AUTOSAR XML (schema 4-3-1)
standard types defined: Boolean, UInt8, SInt8, UInt16, SInt16, UInt32, SInt32, boolean, uint8, sint8, uint16, sint16, uint32, sint32
package /Components
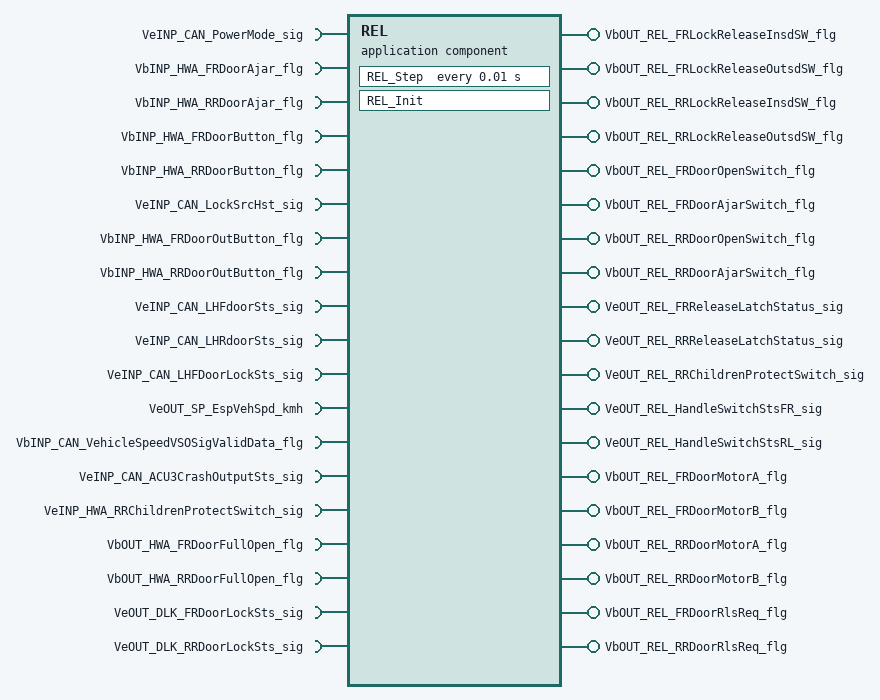
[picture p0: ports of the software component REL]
  application sw component type REL
    19 x require port:
      VeINP_CAN_PowerMode_sig: nonqueued-receiver-com-spec{data-element=VeINP_CAN_PowerMode_sig, init-value=0}, required-interface=VeINP_CAN_PowerMode_sig
      VbINP_HWA_FRDoorAjar_flg: nonqueued-receiver-com-spec{data-element=VbINP_HWA_FRDoorAjar_flg, init-value=FALSE}, required-interface=VbINP_HWA_FRDoorAjar_flg
      VbINP_HWA_RRDoorAjar_flg: nonqueued-receiver-com-spec{data-element=VbINP_HWA_RRDoorAjar_flg, init-value=FALSE}, required-interface=VbINP_HWA_RRDoorAjar_flg
      VbINP_HWA_FRDoorButton_flg: nonqueued-receiver-com-spec{data-element=VbINP_HWA_FRDoorButton_flg, init-value=FALSE}, required-interface=VbINP_HWA_FRDoorButton_flg
      VbINP_HWA_RRDoorButton_flg: nonqueued-receiver-com-spec{data-element=VbINP_HWA_RRDoorButton_flg, init-value=FALSE}, required-interface=VbINP_HWA_RRDoorButton_flg
      VeINP_CAN_LockSrcHst_sig: nonqueued-receiver-com-spec{data-element=VeINP_CAN_LockSrcHst_sig, init-value=0}, required-interface=VeINP_CAN_LockSrcHst_sig
      VbINP_HWA_FRDoorOutButton_flg: nonqueued-receiver-com-spec{data-element=VbINP_HWA_FRDoorOutButton_flg, init-value=FALSE}, required-interface=VbINP_HWA_FRDoorOutButton_flg
      VbINP_HWA_RRDoorOutButton_flg: nonqueued-receiver-com-spec{data-element=VbINP_HWA_RRDoorOutButton_flg, init-value=FALSE}, required-interface=VbINP_HWA_RRDoorOutButton_flg
      VeINP_CAN_LHFdoorSts_sig: nonqueued-receiver-com-spec{data-element=VeINP_CAN_LHFdoorSts_sig, init-value=0}, required-interface=VeINP_CAN_LHFdoorSts_sig
      VeINP_CAN_LHRdoorSts_sig: nonqueued-receiver-com-spec{data-element=VeINP_CAN_LHRdoorSts_sig, init-value=0}, required-interface=VeINP_CAN_LHRdoorSts_sig
      VeINP_CAN_LHFDoorLockSts_sig: nonqueued-receiver-com-spec{data-element=VeINP_CAN_LHFDoorLockSts_sig, init-value=0}, required-interface=VeINP_CAN_LHFDoorLockSts_sig
      VeOUT_SP_EspVehSpd_kmh: nonqueued-receiver-com-spec{data-element=VeOUT_SP_EspVehSpd_kmh, init-value=0}, required-interface=VeOUT_SP_EspVehSpd_kmh
      VbINP_CAN_VehicleSpeedVSOSigValidData_flg: nonqueued-receiver-com-spec{data-element=VbINP_CAN_VehicleSpeedVSOSigValidData_flg, init-value=FALSE}, required-interface=VbINP_CAN_VehicleSpeedVSOSigValidData_flg
      VeINP_CAN_ACU3CrashOutputSts_sig: nonqueued-receiver-com-spec{data-element=VeINP_CAN_ACU3CrashOutputSts_sig, init-value=0}, required-interface=VeINP_CAN_ACU3CrashOutputSts_sig
      VeINP_HWA_RRChildrenProtectSwitch_sig: nonqueued-receiver-com-spec{data-element=VeINP_HWA_RRChildrenProtectSwitch_sig, init-value=0}, required-interface=VeINP_HWA_RRChildrenProtectSwitch_sig
      VbOUT_HWA_FRDoorFullOpen_flg: nonqueued-receiver-com-spec{data-element=VbOUT_HWA_FRDoorFullOpen_flg, init-value=FALSE}, required-interface=VbOUT_HWA_FRDoorFullOpen_flg
      VbOUT_HWA_RRDoorFullOpen_flg: nonqueued-receiver-com-spec{data-element=VbOUT_HWA_RRDoorFullOpen_flg, init-value=FALSE}, required-interface=VbOUT_HWA_RRDoorFullOpen_flg
      VeOUT_DLK_FRDoorLockSts_sig: nonqueued-receiver-com-spec{data-element=VeOUT_DLK_FRDoorLockSts_sig, init-value=0}, required-interface=VeOUT_DLK_FRDoorLockSts_sig
      VeOUT_DLK_RRDoorLockSts_sig: nonqueued-receiver-com-spec{data-element=VeOUT_DLK_RRDoorLockSts_sig, init-value=0}, required-interface=VeOUT_DLK_RRDoorLockSts_sig
    19 x provide port:
      VbOUT_REL_FRLockReleaseInsdSW_flg: nonqueued-sender-com-spec{data-element=VbOUT_REL_FRLockReleaseInsdSW_flg, init-value=FALSE}, provided-interface=VbOUT_REL_FRLockReleaseInsdSW_flg
      VbOUT_REL_FRLockReleaseOutsdSW_flg: nonqueued-sender-com-spec{data-element=VbOUT_REL_FRLockReleaseOutsdSW_flg, init-value=FALSE}, provided-interface=VbOUT_REL_FRLockReleaseOutsdSW_flg
      VbOUT_REL_RRLockReleaseInsdSW_flg: nonqueued-sender-com-spec{data-element=VbOUT_REL_RRLockReleaseInsdSW_flg, init-value=FALSE}, provided-interface=VbOUT_REL_RRLockReleaseInsdSW_flg
      VbOUT_REL_RRLockReleaseOutsdSW_flg: nonqueued-sender-com-spec{data-element=VbOUT_REL_RRLockReleaseOutsdSW_flg, init-value=FALSE}, provided-interface=VbOUT_REL_RRLockReleaseOutsdSW_flg
      VbOUT_REL_FRDoorOpenSwitch_flg: nonqueued-sender-com-spec{data-element=VbOUT_REL_FRDoorOpenSwitch_flg, init-value=FALSE}, provided-interface=VbOUT_REL_FRDoorOpenSwitch_flg
      VbOUT_REL_FRDoorAjarSwitch_flg: nonqueued-sender-com-spec{data-element=VbOUT_REL_FRDoorAjarSwitch_flg, init-value=FALSE}, provided-interface=VbOUT_REL_FRDoorAjarSwitch_flg
      VbOUT_REL_RRDoorOpenSwitch_flg: nonqueued-sender-com-spec{data-element=VbOUT_REL_RRDoorOpenSwitch_flg, init-value=FALSE}, provided-interface=VbOUT_REL_RRDoorOpenSwitch_flg
      VbOUT_REL_RRDoorAjarSwitch_flg: nonqueued-sender-com-spec{data-element=VbOUT_REL_RRDoorAjarSwitch_flg, init-value=FALSE}, provided-interface=VbOUT_REL_RRDoorAjarSwitch_flg
      VeOUT_REL_FRReleaseLatchStatus_sig: nonqueued-sender-com-spec{data-element=VeOUT_REL_FRReleaseLatchStatus_sig, init-value=0}, provided-interface=VeOUT_REL_FRReleaseLatchStatus_sig
      VeOUT_REL_RRReleaseLatchStatus_sig: nonqueued-sender-com-spec{data-element=VeOUT_REL_RRReleaseLatchStatus_sig, init-value=0}, provided-interface=VeOUT_REL_RRReleaseLatchStatus_sig
      VeOUT_REL_RRChildrenProtectSwitch_sig: nonqueued-sender-com-spec{data-element=VeOUT_REL_RRChildrenProtectSwitch_sig, init-value=0}, provided-interface=VeOUT_REL_RRChildrenProtectSwitch_sig
      VeOUT_REL_HandleSwitchStsFR_sig: nonqueued-sender-com-spec{data-element=VeOUT_REL_HandleSwitchStsFR_sig, init-value=0}, provided-interface=VeOUT_REL_HandleSwitchStsFR_sig
      VeOUT_REL_HandleSwitchStsRL_sig: nonqueued-sender-com-spec{data-element=VeOUT_REL_HandleSwitchStsRL_sig, init-value=0}, provided-interface=VeOUT_REL_HandleSwitchStsRL_sig
      VbOUT_REL_FRDoorMotorA_flg: nonqueued-sender-com-spec{data-element=VbOUT_REL_FRDoorMotorA_flg, init-value=FALSE}, provided-interface=VbOUT_REL_FRDoorMotorA_flg
      VbOUT_REL_FRDoorMotorB_flg: nonqueued-sender-com-spec{data-element=VbOUT_REL_FRDoorMotorB_flg, init-value=FALSE}, provided-interface=VbOUT_REL_FRDoorMotorB_flg
      VbOUT_REL_RRDoorMotorA_flg: nonqueued-sender-com-spec{data-element=VbOUT_REL_RRDoorMotorA_flg, init-value=FALSE}, provided-interface=VbOUT_REL_RRDoorMotorA_flg
      VbOUT_REL_RRDoorMotorB_flg: nonqueued-sender-com-spec{data-element=VbOUT_REL_RRDoorMotorB_flg, init-value=FALSE}, provided-interface=VbOUT_REL_RRDoorMotorB_flg
      VbOUT_REL_FRDoorRlsReq_flg: nonqueued-sender-com-spec{data-element=VbOUT_REL_FRDoorRlsReq_flg, init-value=FALSE}, provided-interface=VbOUT_REL_FRDoorRlsReq_flg
      VbOUT_REL_RRDoorRlsReq_flg: nonqueued-sender-com-spec{data-element=VbOUT_REL_RRDoorRlsReq_flg, init-value=FALSE}, provided-interface=VbOUT_REL_RRDoorRlsReq_flg
    behavior REL: data-type-mapping=DataTypeMappingsSet, handle-termination-and-restart=NO-SUPPORT
      init event REL_InitEvent: start-on-event=REL_Init
      timing event Event_Runnable_Step: start-on-event=REL_Step, period=0.01
      runnable REL_Init
        data-send-points:
          6 x access:
            OUT_VbOUT_REL_FRDoorMotorA_flg_VbOUT_REL_FRDoorMotorA_flg: accessed-variable=VbOUT_REL_FRDoorMotorA_flg.VbOUT_REL_FRDoorMotorA_flg
            OUT_VbOUT_REL_FRDoorMotorB_flg_VbOUT_REL_FRDoorMotorB_flg: accessed-variable=VbOUT_REL_FRDoorMotorB_flg.VbOUT_REL_FRDoorMotorB_flg
            OUT_VbOUT_REL_RRDoorMotorA_flg_VbOUT_REL_RRDoorMotorA_flg: accessed-variable=VbOUT_REL_RRDoorMotorA_flg.VbOUT_REL_RRDoorMotorA_flg
            OUT_VbOUT_REL_RRDoorMotorB_flg_VbOUT_REL_RRDoorMotorB_flg: accessed-variable=VbOUT_REL_RRDoorMotorB_flg.VbOUT_REL_RRDoorMotorB_flg
            OUT_VbOUT_REL_FRDoorRlsReq_flg_VbOUT_REL_FRDoorRlsReq_flg: accessed-variable=VbOUT_REL_FRDoorRlsReq_flg.VbOUT_REL_FRDoorRlsReq_flg
            OUT_VbOUT_REL_RRDoorRlsReq_flg_VbOUT_REL_RRDoorRlsReq_flg: accessed-variable=VbOUT_REL_RRDoorRlsReq_flg.VbOUT_REL_RRDoorRlsReq_flg
      runnable REL_Step
        data-receive-point-by-arguments:
          15 x access:
            IN_VbINP_CAN_VehicleSpeedVSOSigValidData_flg_VbINP_CAN_VehicleSpeedVSOSigValidData_flg: accessed-variable=VbINP_CAN_VehicleSpeedVSOSigValidData_flg.VbINP_CAN_VehicleSpeedVSOSigValidData_flg
            IN_VbINP_HWA_FRDoorAjar_flg_VbINP_HWA_FRDoorAjar_flg: accessed-variable=VbINP_HWA_FRDoorAjar_flg.VbINP_HWA_FRDoorAjar_flg
            IN_VbINP_HWA_FRDoorButton_flg_VbINP_HWA_FRDoorButton_flg: accessed-variable=VbINP_HWA_FRDoorButton_flg.VbINP_HWA_FRDoorButton_flg
            IN_VbINP_HWA_FRDoorOutButton_flg_VbINP_HWA_FRDoorOutButton_flg: accessed-variable=VbINP_HWA_FRDoorOutButton_flg.VbINP_HWA_FRDoorOutButton_flg
            IN_VbINP_HWA_RRDoorAjar_flg_VbINP_HWA_RRDoorAjar_flg: accessed-variable=VbINP_HWA_RRDoorAjar_flg.VbINP_HWA_RRDoorAjar_flg
            IN_VbINP_HWA_RRDoorButton_flg_VbINP_HWA_RRDoorButton_flg: accessed-variable=VbINP_HWA_RRDoorButton_flg.VbINP_HWA_RRDoorButton_flg
            IN_VbINP_HWA_RRDoorOutButton_flg_VbINP_HWA_RRDoorOutButton_flg: accessed-variable=VbINP_HWA_RRDoorOutButton_flg.VbINP_HWA_RRDoorOutButton_flg
            IN_VbOUT_HWA_FRDoorFullOpen_flg_VbOUT_HWA_FRDoorFullOpen_flg: accessed-variable=VbOUT_HWA_FRDoorFullOpen_flg.VbOUT_HWA_FRDoorFullOpen_flg
            IN_VbOUT_HWA_RRDoorFullOpen_flg_VbOUT_HWA_RRDoorFullOpen_flg: accessed-variable=VbOUT_HWA_RRDoorFullOpen_flg.VbOUT_HWA_RRDoorFullOpen_flg
            IN_VeINP_CAN_ACU3CrashOutputSts_sig_VeINP_CAN_ACU3CrashOutputSts_sig: accessed-variable=VeINP_CAN_ACU3CrashOutputSts_sig.VeINP_CAN_ACU3CrashOutputSts_sig
            IN_VeINP_CAN_PowerMode_sig_VeINP_CAN_PowerMode_sig: accessed-variable=VeINP_CAN_PowerMode_sig.VeINP_CAN_PowerMode_sig
            IN_VeINP_HWA_RRChildrenProtectSwitch_sig_VeINP_HWA_RRChildrenProtectSwitch_sig: accessed-variable=VeINP_HWA_RRChildrenProtectSwitch_sig.VeINP_HWA_RRChildrenProtectSwitch_sig
            IN_VeOUT_DLK_FRDoorLockSts_sig_VeOUT_DLK_FRDoorLockSts_sig: accessed-variable=VeOUT_DLK_FRDoorLockSts_sig.VeOUT_DLK_FRDoorLockSts_sig
            IN_VeOUT_DLK_RRDoorLockSts_sig_VeOUT_DLK_RRDoorLockSts_sig: accessed-variable=VeOUT_DLK_RRDoorLockSts_sig.VeOUT_DLK_RRDoorLockSts_sig
            IN_VeOUT_SP_EspVehSpd_kmh_VeOUT_SP_EspVehSpd_kmh: accessed-variable=VeOUT_SP_EspVehSpd_kmh.VeOUT_SP_EspVehSpd_kmh
        data-send-points:
          19 x access:
            OUT_VbOUT_REL_FRLockReleaseInsdSW_flg_VbOUT_REL_FRLockReleaseInsdSW_flg: accessed-variable=VbOUT_REL_FRLockReleaseInsdSW_flg.VbOUT_REL_FRLockReleaseInsdSW_flg
            OUT_VbOUT_REL_FRLockReleaseOutsdSW_flg_VbOUT_REL_FRLockReleaseOutsdSW_flg: accessed-variable=VbOUT_REL_FRLockReleaseOutsdSW_flg.VbOUT_REL_FRLockReleaseOutsdSW_flg
            OUT_VbOUT_REL_RRLockReleaseInsdSW_flg_VbOUT_REL_RRLockReleaseInsdSW_flg: accessed-variable=VbOUT_REL_RRLockReleaseInsdSW_flg.VbOUT_REL_RRLockReleaseInsdSW_flg
            OUT_VbOUT_REL_RRLockReleaseOutsdSW_flg_VbOUT_REL_RRLockReleaseOutsdSW_flg: accessed-variable=VbOUT_REL_RRLockReleaseOutsdSW_flg.VbOUT_REL_RRLockReleaseOutsdSW_flg
            OUT_VbOUT_REL_FRDoorOpenSwitch_flg_VbOUT_REL_FRDoorOpenSwitch_flg: accessed-variable=VbOUT_REL_FRDoorOpenSwitch_flg.VbOUT_REL_FRDoorOpenSwitch_flg
            OUT_VbOUT_REL_FRDoorAjarSwitch_flg_VbOUT_REL_FRDoorAjarSwitch_flg: accessed-variable=VbOUT_REL_FRDoorAjarSwitch_flg.VbOUT_REL_FRDoorAjarSwitch_flg
            OUT_VbOUT_REL_RRDoorOpenSwitch_flg_VbOUT_REL_RRDoorOpenSwitch_flg: accessed-variable=VbOUT_REL_RRDoorOpenSwitch_flg.VbOUT_REL_RRDoorOpenSwitch_flg
            OUT_VbOUT_REL_RRDoorAjarSwitch_flg_VbOUT_REL_RRDoorAjarSwitch_flg: accessed-variable=VbOUT_REL_RRDoorAjarSwitch_flg.VbOUT_REL_RRDoorAjarSwitch_flg
            OUT_VeOUT_REL_FRReleaseLatchStatus_sig_VeOUT_REL_FRReleaseLatchStatus_sig: accessed-variable=VeOUT_REL_FRReleaseLatchStatus_sig.VeOUT_REL_FRReleaseLatchStatus_sig
            OUT_VeOUT_REL_RRReleaseLatchStatus_sig_VeOUT_REL_RRReleaseLatchStatus_sig: accessed-variable=VeOUT_REL_RRReleaseLatchStatus_sig.VeOUT_REL_RRReleaseLatchStatus_sig
            OUT_VeOUT_REL_RRChildrenProtectSwitch_sig_VeOUT_REL_RRChildrenProtectSwitch_sig: accessed-variable=VeOUT_REL_RRChildrenProtectSwitch_sig.VeOUT_REL_RRChildrenProtectSwitch_sig
            OUT_VeOUT_REL_HandleSwitchStsFR_sig_VeOUT_REL_HandleSwitchStsFR_sig: accessed-variable=VeOUT_REL_HandleSwitchStsFR_sig.VeOUT_REL_HandleSwitchStsFR_sig
            OUT_VeOUT_REL_HandleSwitchStsRL_sig_VeOUT_REL_HandleSwitchStsRL_sig: accessed-variable=VeOUT_REL_HandleSwitchStsRL_sig.VeOUT_REL_HandleSwitchStsRL_sig
            OUT_VbOUT_REL_FRDoorMotorA_flg_VbOUT_REL_FRDoorMotorA_flg: accessed-variable=VbOUT_REL_FRDoorMotorA_flg.VbOUT_REL_FRDoorMotorA_flg
            OUT_VbOUT_REL_FRDoorMotorB_flg_VbOUT_REL_FRDoorMotorB_flg: accessed-variable=VbOUT_REL_FRDoorMotorB_flg.VbOUT_REL_FRDoorMotorB_flg
            OUT_VbOUT_REL_RRDoorMotorA_flg_VbOUT_REL_RRDoorMotorA_flg: accessed-variable=VbOUT_REL_RRDoorMotorA_flg.VbOUT_REL_RRDoorMotorA_flg
            OUT_VbOUT_REL_RRDoorMotorB_flg_VbOUT_REL_RRDoorMotorB_flg: accessed-variable=VbOUT_REL_RRDoorMotorB_flg.VbOUT_REL_RRDoorMotorB_flg
            OUT_VbOUT_REL_FRDoorRlsReq_flg_VbOUT_REL_FRDoorRlsReq_flg: accessed-variable=VbOUT_REL_FRDoorRlsReq_flg.VbOUT_REL_FRDoorRlsReq_flg
            OUT_VbOUT_REL_RRDoorRlsReq_flg_VbOUT_REL_RRDoorRlsReq_flg: accessed-variable=VbOUT_REL_RRDoorRlsReq_flg.VbOUT_REL_RRDoorRlsReq_flg
package /DataTypes/ApplicationDataTypes
  application array data type rt_Array_UInt8_20: category=ARRAY, sw-calibration-access=READ-WRITE
    element rt_Array_UInt8_20: category=VALUE, type=UInt8, array-size-semantics=FIXED-SIZE, max-number-of-elements=20
  7 x app type, all with sw-calibration-access=READ-WRITE:
    Boolean: category=BOOLEAN, compu {0=FALSE, 1=TRUE}
    UInt8: category=VALUE, compu {identical}, range phys 0..255
    SInt8: category=VALUE, compu {identical}, range phys -128..127
    UInt16: category=VALUE, compu {identical}, range phys 0..65535
    SInt16: category=VALUE, compu {identical}, range phys -32768..32767
    UInt32: category=VALUE, compu {identical}, range phys 0..4294967295
    SInt32: category=VALUE, compu {identical}, range phys -2147483648..2147483647
package /DataTypes/DataTypeMappings
  data type mapping set DataTypeMappingsSet
    data-type-maps:
      application-data-type=Boolean, implementation-data-type=Boolean
      application-data-type=UInt8, implementation-data-type=UInt8
      application-data-type=SInt8, implementation-data-type=SInt8
      application-data-type=UInt16, implementation-data-type=UInt16
      application-data-type=SInt16, implementation-data-type=SInt16
      application-data-type=UInt32, implementation-data-type=UInt32
      application-data-type=SInt32, implementation-data-type=SInt32
      application-data-type=rt_Array_UInt8_20, implementation-data-type=rt_Array_UInt8_20
package /DataTypes/ImplementationDataTypes
  impl type rt_Array_UInt8_20: category=ARRAY
    element rt_Array_UInt8_20: array-size=20, array-size-semantics=FIXED-SIZE, implementation-data-type=UInt8
package /DataTypes/SwAddrMethods
  sw addr method CODE: section-type=CODE
  sw addr method CONST: section-type=CONST
  sw addr method VAR: section-type=VAR
package /DataTypes/Units
  unit NoUnit: factor-si-to-unit=1, offset-si-to-unit=0
package /Interfaces
  38 x sender receiver interface:
    VeINP_CAN_PowerMode_sig
      data VeINP_CAN_PowerMode_sig: category=VALUE, sw-calibration-access=READ-ONLY, type=UInt8
    VbINP_HWA_FRDoorAjar_flg
      data VbINP_HWA_FRDoorAjar_flg: category=BOOLEAN, sw-calibration-access=READ-ONLY, type=Boolean
    VbINP_HWA_RRDoorAjar_flg
      data VbINP_HWA_RRDoorAjar_flg: category=BOOLEAN, sw-calibration-access=READ-ONLY, type=Boolean
    VbINP_HWA_FRDoorButton_flg
      data VbINP_HWA_FRDoorButton_flg: category=BOOLEAN, sw-calibration-access=READ-ONLY, type=Boolean
    VbINP_HWA_RRDoorButton_flg
      data VbINP_HWA_RRDoorButton_flg: category=BOOLEAN, sw-calibration-access=READ-ONLY, type=Boolean
    VeINP_CAN_LockSrcHst_sig
      data VeINP_CAN_LockSrcHst_sig: category=VALUE, sw-calibration-access=READ-ONLY, type=UInt8
    VbINP_HWA_FRDoorOutButton_flg
      data VbINP_HWA_FRDoorOutButton_flg: category=BOOLEAN, sw-calibration-access=READ-ONLY, type=Boolean
    VbINP_HWA_RRDoorOutButton_flg
      data VbINP_HWA_RRDoorOutButton_flg: category=BOOLEAN, sw-calibration-access=READ-ONLY, type=Boolean
    VeINP_CAN_LHFdoorSts_sig
      data VeINP_CAN_LHFdoorSts_sig: category=VALUE, sw-calibration-access=READ-ONLY, type=UInt8
    VeINP_CAN_LHRdoorSts_sig
      data VeINP_CAN_LHRdoorSts_sig: category=VALUE, sw-calibration-access=READ-ONLY, type=UInt8
    VeINP_CAN_LHFDoorLockSts_sig
      data VeINP_CAN_LHFDoorLockSts_sig: category=VALUE, sw-calibration-access=READ-ONLY, type=UInt8
    VeOUT_SP_EspVehSpd_kmh
      data VeOUT_SP_EspVehSpd_kmh: category=VALUE, sw-calibration-access=READ-ONLY, type=UInt8
    VbINP_CAN_VehicleSpeedVSOSigValidData_flg
      data VbINP_CAN_VehicleSpeedVSOSigValidData_flg: category=BOOLEAN, sw-calibration-access=READ-ONLY, type=Boolean
    VeINP_CAN_ACU3CrashOutputSts_sig
      data VeINP_CAN_ACU3CrashOutputSts_sig: category=VALUE, sw-calibration-access=READ-ONLY, type=UInt8
    VeINP_HWA_RRChildrenProtectSwitch_sig
      data VeINP_HWA_RRChildrenProtectSwitch_sig: category=VALUE, sw-calibration-access=READ-ONLY, type=UInt8
    VbOUT_HWA_FRDoorFullOpen_flg
      data VbOUT_HWA_FRDoorFullOpen_flg: category=BOOLEAN, sw-calibration-access=READ-ONLY, type=Boolean
    VbOUT_HWA_RRDoorFullOpen_flg
      data VbOUT_HWA_RRDoorFullOpen_flg: category=BOOLEAN, sw-calibration-access=READ-ONLY, type=Boolean
    VeOUT_DLK_FRDoorLockSts_sig
      data VeOUT_DLK_FRDoorLockSts_sig: category=VALUE, sw-calibration-access=READ-ONLY, type=UInt8
    VeOUT_DLK_RRDoorLockSts_sig
      data VeOUT_DLK_RRDoorLockSts_sig: category=VALUE, sw-calibration-access=READ-ONLY, type=UInt8
    VbOUT_REL_FRLockReleaseInsdSW_flg
      data VbOUT_REL_FRLockReleaseInsdSW_flg: category=BOOLEAN, sw-calibration-access=READ-ONLY, type=Boolean
    VbOUT_REL_FRLockReleaseOutsdSW_flg
      data VbOUT_REL_FRLockReleaseOutsdSW_flg: category=BOOLEAN, sw-calibration-access=READ-ONLY, type=Boolean
    VbOUT_REL_RRLockReleaseInsdSW_flg
      data VbOUT_REL_RRLockReleaseInsdSW_flg: category=BOOLEAN, sw-calibration-access=READ-ONLY, type=Boolean
    VbOUT_REL_RRLockReleaseOutsdSW_flg
      data VbOUT_REL_RRLockReleaseOutsdSW_flg: category=BOOLEAN, sw-calibration-access=READ-ONLY, type=Boolean
    VbOUT_REL_FRDoorOpenSwitch_flg
      data VbOUT_REL_FRDoorOpenSwitch_flg: category=BOOLEAN, sw-calibration-access=READ-ONLY, type=Boolean
    VbOUT_REL_FRDoorAjarSwitch_flg
      data VbOUT_REL_FRDoorAjarSwitch_flg: category=BOOLEAN, sw-calibration-access=READ-ONLY, type=Boolean
    VbOUT_REL_RRDoorOpenSwitch_flg
      data VbOUT_REL_RRDoorOpenSwitch_flg: category=BOOLEAN, sw-calibration-access=READ-ONLY, type=Boolean
    VbOUT_REL_RRDoorAjarSwitch_flg
      data VbOUT_REL_RRDoorAjarSwitch_flg: category=BOOLEAN, sw-calibration-access=READ-ONLY, type=Boolean
    VeOUT_REL_FRReleaseLatchStatus_sig
      data VeOUT_REL_FRReleaseLatchStatus_sig: category=VALUE, sw-calibration-access=READ-ONLY, type=UInt8
    VeOUT_REL_RRReleaseLatchStatus_sig
      data VeOUT_REL_RRReleaseLatchStatus_sig: category=VALUE, sw-calibration-access=READ-ONLY, type=UInt8
    VeOUT_REL_RRChildrenProtectSwitch_sig
      data VeOUT_REL_RRChildrenProtectSwitch_sig: category=VALUE, sw-calibration-access=READ-ONLY, type=UInt8
    VeOUT_REL_HandleSwitchStsFR_sig
      data VeOUT_REL_HandleSwitchStsFR_sig: category=VALUE, sw-calibration-access=READ-ONLY, type=UInt8
    VeOUT_REL_HandleSwitchStsRL_sig
      data VeOUT_REL_HandleSwitchStsRL_sig: category=VALUE, sw-calibration-access=READ-ONLY, type=UInt8
    VbOUT_REL_FRDoorMotorA_flg
      data VbOUT_REL_FRDoorMotorA_flg: category=BOOLEAN, sw-calibration-access=READ-ONLY, type=Boolean
    VbOUT_REL_FRDoorMotorB_flg
      data VbOUT_REL_FRDoorMotorB_flg: category=BOOLEAN, sw-calibration-access=READ-ONLY, type=Boolean
    VbOUT_REL_RRDoorMotorA_flg
      data VbOUT_REL_RRDoorMotorA_flg: category=BOOLEAN, sw-calibration-access=READ-ONLY, type=Boolean
    VbOUT_REL_RRDoorMotorB_flg
      data VbOUT_REL_RRDoorMotorB_flg: category=BOOLEAN, sw-calibration-access=READ-ONLY, type=Boolean
    VbOUT_REL_FRDoorRlsReq_flg
      data VbOUT_REL_FRDoorRlsReq_flg: category=BOOLEAN, sw-calibration-access=READ-ONLY, type=Boolean
    VbOUT_REL_RRDoorRlsReq_flg
      data VbOUT_REL_RRDoorRlsReq_flg: category=BOOLEAN, sw-calibration-access=READ-ONLY, type=Boolean
